# CY8C5888LTI_LP097 register map
File version: 0.1
CY8C58LP
Registers are 8-bit, read-write, no defined reset value unless marked. A register's access mark holds for its fields unless they carry their own. Offsets are from the block's base; lines under a group give offsets from that group; [hi:lo] are bit positions; {n}, {i} and the like mark numbered series; 'fields as' and 'values as' point back to an identical list; <NAME> marks a mode.

## Memory map
0x00000000 Status_Reg_UltraSoon_3
0x00000000 Status_Reg_UltraSoon_1
0x00000000 Status_Reg_UltraSoon_2
0x00000000 PWM_1
0x00000000 ADC_SAR_Seq_1_SAR — SAR ADC
0x00000000 I2C

## Status_Reg_UltraSoon_3
Base 0x00000000
0x40006567 Status_Reg_UltraSoon_3_STATUS_REG
0x40006587 Status_Reg_UltraSoon_3_MASK_REG
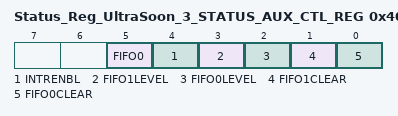
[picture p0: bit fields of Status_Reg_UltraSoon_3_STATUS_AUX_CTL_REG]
0x40006597 Status_Reg_UltraSoon_3_STATUS_AUX_CTL_REG
  [5] FIFO0 — FIFO0 clear
    1=ENABLED (Enable counter); 0=DISABLED (Disable counter)
  [4] INTRENBL — Enables or disables the Interrupt
    1=ENABLED (Interrupt enabled); 0=DISABLED (Interrupt disabled)
  [3] FIFO1LEVEL — FIFO level
    1=ENABLED (FIFO LVL: input mode: FIFO at least 1/2 empty; output mode: FIFO at least 1/2 full); 0=DISABLED (FIFO LVL: input mode: FIFO not full; output mode: FIFO not empty)
  [2] FIFO0LEVEL — FIFO level
    values as FIFO1LEVEL
  [1] FIFO1CLEAR — FIFO clear
    1=ENABLED (Clear FIFO state); 0=DISABLED (Normal FIFO operation)
  [0] FIFO0CLEAR — FIFO clear
    values as FIFO1CLEAR

## Status_Reg_UltraSoon_1
Base 0x00000000
0x40006568 Status_Reg_UltraSoon_1_STATUS_REG
0x40006588 Status_Reg_UltraSoon_1_MASK_REG
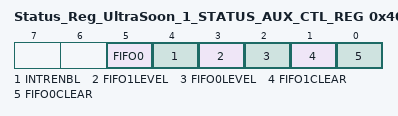
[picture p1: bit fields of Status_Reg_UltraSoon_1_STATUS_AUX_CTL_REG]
0x40006598 Status_Reg_UltraSoon_1_STATUS_AUX_CTL_REG
  [5] FIFO0 — FIFO0 clear
    1=ENABLED (Enable counter); 0=DISABLED (Disable counter)
  [4] INTRENBL — Enables or disables the Interrupt
    1=ENABLED (Interrupt enabled); 0=DISABLED (Interrupt disabled)
  [3] FIFO1LEVEL — FIFO level
    1=ENABLED (FIFO LVL: input mode: FIFO at least 1/2 empty; output mode: FIFO at least 1/2 full); 0=DISABLED (FIFO LVL: input mode: FIFO not full; output mode: FIFO not empty)
  [2] FIFO0LEVEL — FIFO level
    values as FIFO1LEVEL
  [1] FIFO1CLEAR — FIFO clear
    1=ENABLED (Clear FIFO state); 0=DISABLED (Normal FIFO operation)
  [0] FIFO0CLEAR — FIFO clear
    values as FIFO1CLEAR

## Status_Reg_UltraSoon_2
Base 0x00000000
0x4000646E Status_Reg_UltraSoon_2_STATUS_REG
0x4000648E Status_Reg_UltraSoon_2_MASK_REG
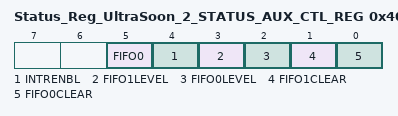
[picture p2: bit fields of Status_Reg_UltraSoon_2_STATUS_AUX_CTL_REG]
0x4000649E Status_Reg_UltraSoon_2_STATUS_AUX_CTL_REG
  [5] FIFO0 — FIFO0 clear
    1=ENABLED (Enable counter); 0=DISABLED (Disable counter)
  [4] INTRENBL — Enables or disables the Interrupt
    1=ENABLED (Interrupt enabled); 0=DISABLED (Interrupt disabled)
  [3] FIFO1LEVEL — FIFO level
    1=ENABLED (FIFO LVL: input mode: FIFO at least 1/2 empty; output mode: FIFO at least 1/2 full); 0=DISABLED (FIFO LVL: input mode: FIFO not full; output mode: FIFO not empty)
  [2] FIFO0LEVEL — FIFO level
    values as FIFO1LEVEL
  [1] FIFO1CLEAR — FIFO clear
    1=ENABLED (Clear FIFO state); 0=DISABLED (Normal FIFO operation)
  [0] FIFO0CLEAR — FIFO clear
    values as FIFO1CLEAR

## PWM_1
Base 0x00000000
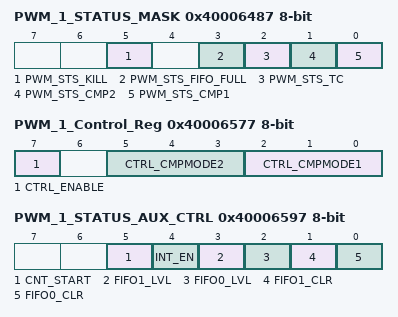
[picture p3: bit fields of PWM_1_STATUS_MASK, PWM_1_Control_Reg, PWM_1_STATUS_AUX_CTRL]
0x40006487 PWM_1_STATUS_MASK — UDB Status bits Interrupt Mask Enable Register
  [5] PWM_STS_KILL ro — Enables the Interrupt on Kill
  [3] PWM_STS_FIFO_FULL ro — FIFO Full Status Mask
  [2] PWM_STS_TC ro — Enables the Interrupt on Terminal Count
  [1] PWM_STS_CMP2 ro — Enables the Interrupt on Compare 2
  [0] PWM_STS_CMP1 ro — Enables the Interrupt on Compare 1
0x40006527 PWM_1__COMPARE1 — UDB.D0 - Assigned Compare1 Value
0x40006537 PWM_1__COMPARE2 — UDB.D1 - Assigned Compare2 Value
0x40006577 PWM_1_Control_Reg — UDB Control Register - Assigned Control Register Value
  [7] CTRL_ENABLE — Enable the PWM
  [5:3] CTRL_CMPMODE2 — Compare mode 2
  [2:0] CTRL_CMPMODE1 — Compare mode 1
0x40006597 PWM_1_STATUS_AUX_CTRL — UDB Auxilliary Control Register
  [5] CNT_START — FIFO0 clear
    0=E_CNT_START0 (Disable counter); 1=E_CNT_START1 (Enable counter)
  [4] INT_EN
    0=E_INT_EN0 (Interrupt disabled); 1=E_INT_EN1 (Interrupt enabled)
  [3] FIFO1_LVL — FIFO level
    0=E_FIFO_LVL_0 (FIFO LVL: input mode: FIFO not full; output mode: FIFO not empty); 1=E_FIFO_LVL_1 (FIFO LVL: input mode: FIFO at least 1/2 empty; output mode: FIFO at least 1/2 full)
  [2] FIFO0_LVL — FIFO level
    values as FIFO1_LVL
  [1] FIFO1_CLR — FIFO1 clear
    0=E_FIFO_CLR_0 (Normal FIFO operation); 1=E_FIFO_CLR_1 (Clear FIFO state)
  [0] FIFO0_CLR — FIFO0 clear
    values as FIFO1_CLR
